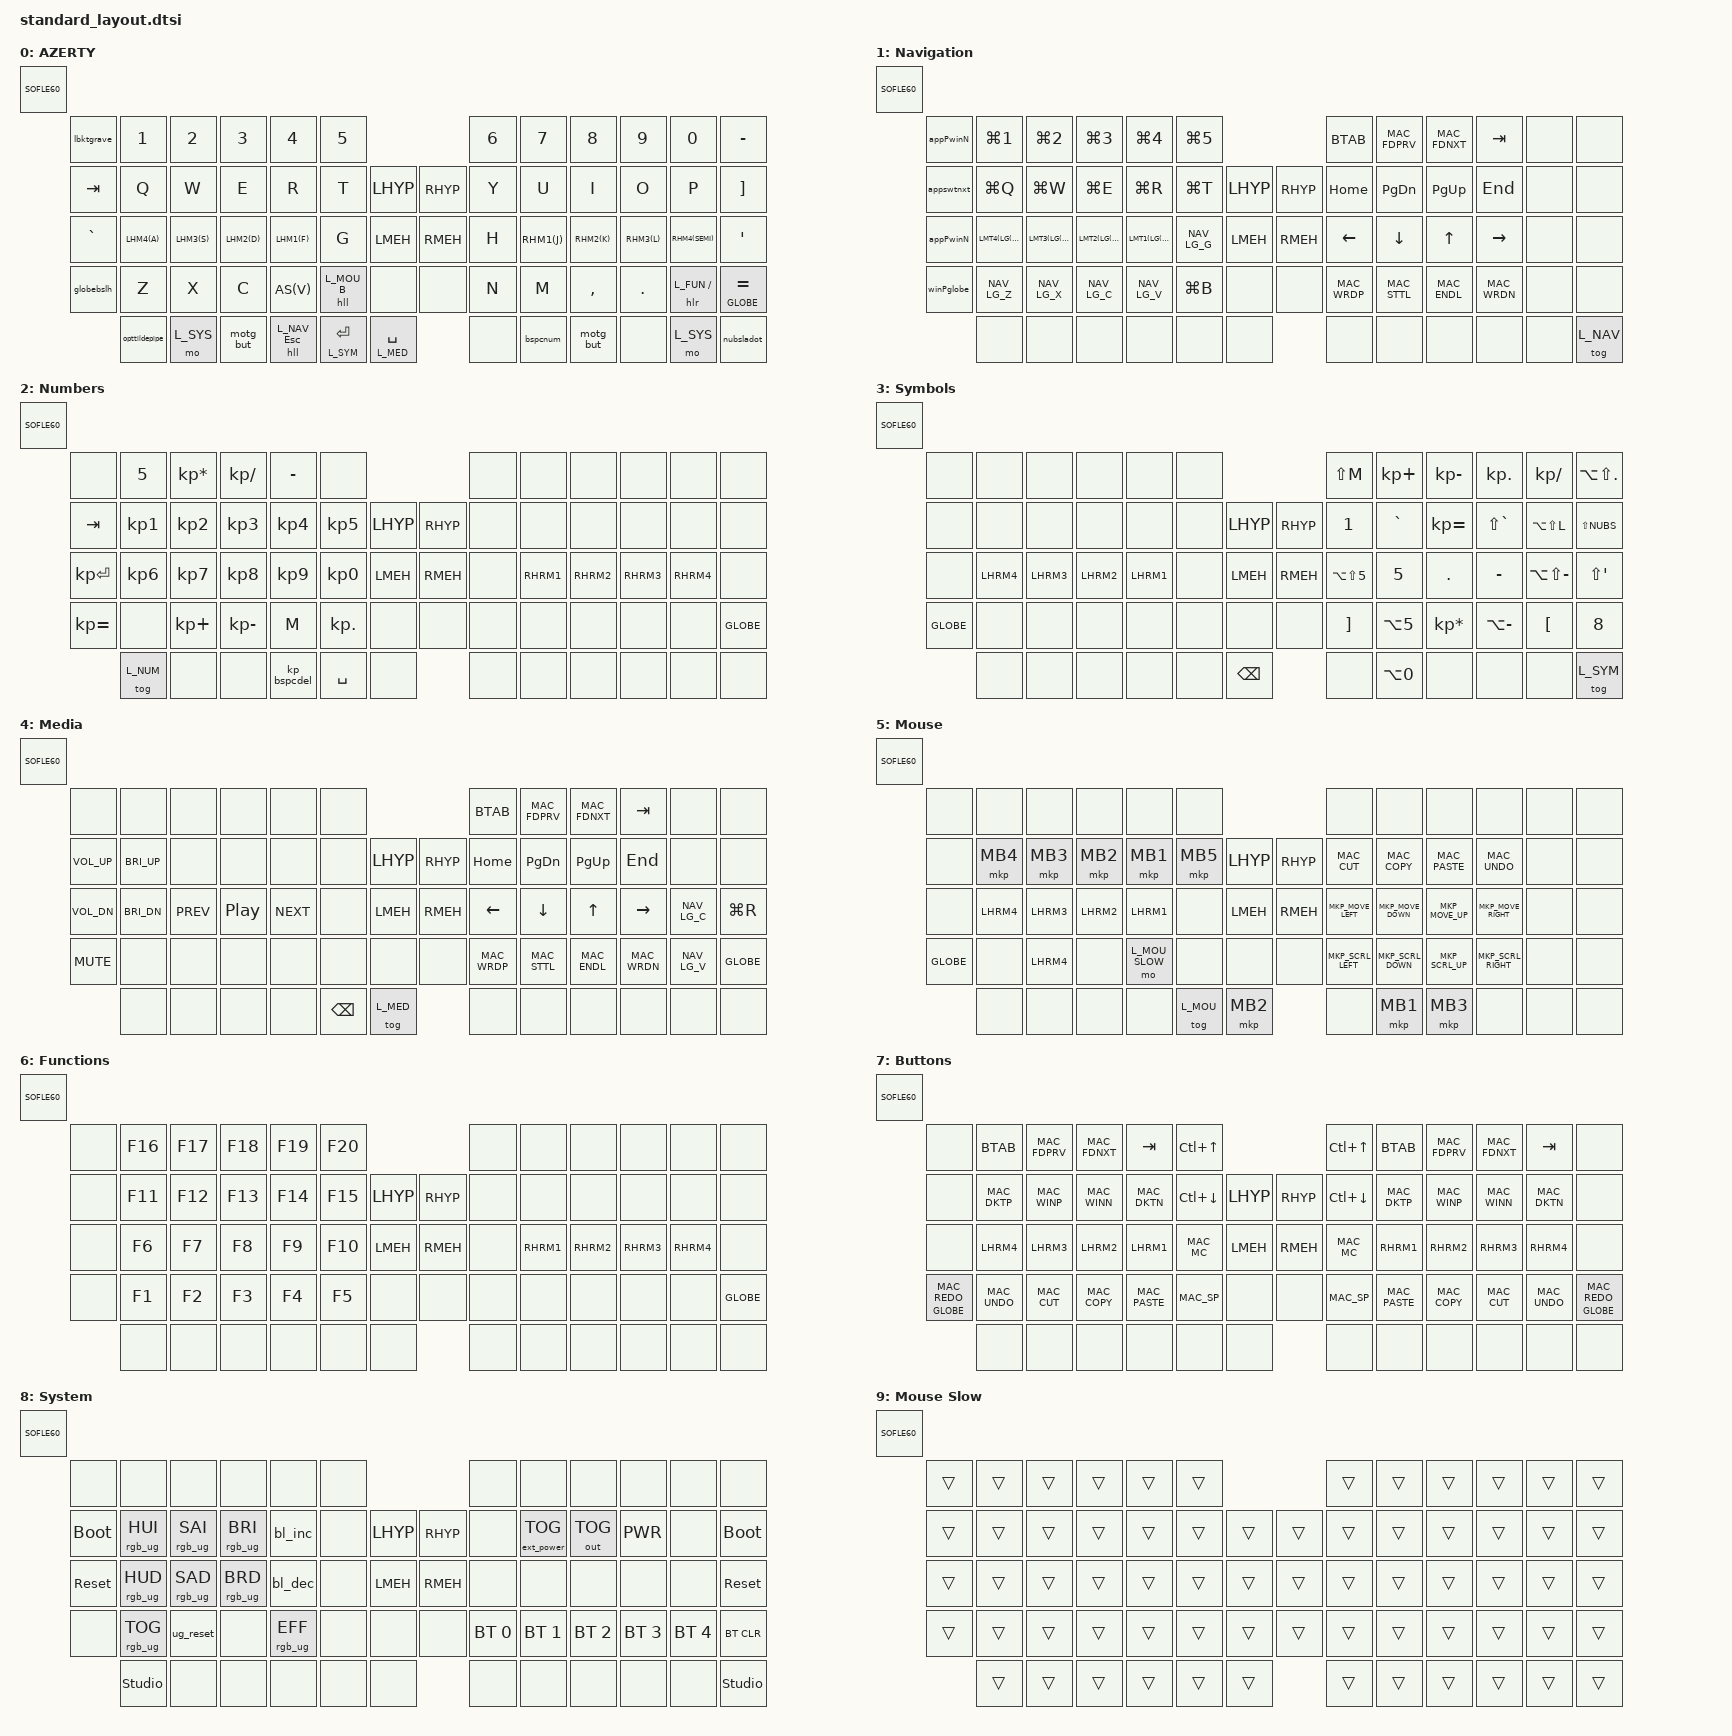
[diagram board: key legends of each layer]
/*
 * Copyright (c) 2024 Thiago Alves
 *
 * SPDX-License-Identifier: MIT
 */

// Éditeur : pas de retour à la ligne forcé sur les longues lignes ; police avec glyphes Nerd Fonts si besoin.

#include <behaviors.dtsi>
#include <dt-bindings/zmk/backlight.h>
#include <dt-bindings/zmk/bt.h>
#include <dt-bindings/zmk/ext_power.h>
#include <dt-bindings/zmk/keys.h>
#include <dt-bindings/zmk/mouse.h>
#include <dt-bindings/zmk/outputs.h>
#include <dt-bindings/zmk/rgb.h>

#include "specialkeys.dtsi"
#include "homerowmods.dtsi"
#include "autoshift.dtsi"
#include "keymap_drawer.dtsi"

#define L_QWT 0
#define L_NAV 1
#define L_NUM 2
#define L_SYM 3
#define L_MED 4
#define L_MOU 5
#define L_FUN 6
#define L_BUT 7
#define L_SYS 8
#define L_MOU_SLOW 9

&caps_word {
  continue-list = <UNDERSCORE MINUS BSPC>;
};

/*
 * Raccourcis P_* : config Sofle actuelle (sofle.keymap) = hold-tap Functions +
 * Mouse, sans hold-tap Buttons. Pour d’autres combinaisons, réintroduire les
 * branches Townk d’origine.
 */
#define P_SF4_QWT  &motg_but
#define P_SF4_BUT  &none
#define P_SB4_BUT  &kp MAC_UNDO
#define P_RB4_QWT  &hlr L_FUN FSLH
#define P_RB3_QWT  &kp DOT
#define P_RF3_QWT  &none
#define P_RF3_FUN  &none
#define P_RB3_FUN  &none
#define P_RB4_FUN  &none
#define P_LT54_NUM  &tog L_NUM
#define P_LT65_NAV  &tog L_NAV
#define P_LT65_SYM  &tog L_SYM
#define P_LB4_QWT  &kp Z
#define P_LB3_QWT  &kp X
#define P_LB5_QWT  &hll L_MOU B
#define P_LF3_QWT  &none
#define P_LF3_MOU  &none
#define P_LB4_MOU  &none
#define P_LT58_MOU  &tog L_MOU
#define P_MOUSE_SLOW  &mo L_MOU_SLOW

#include "mouse.dtsi"

// Comportements dédiés (autres : specialkeys, homerowmods, autoshift)
/ {
  behaviors {
    bspcnav: backspace_or_del_and_layer_nav {
      compatible = "zmk,behavior-mod-morph";
      #binding-cells = <0>;
      bindings = <&hll L_NAV BSPC>, <&kp DEL>;
      mods = <(MOD_LSFT|MOD_RSFT)>;
    };

    bspcnum: backspace_or_del_and_layer_num {
      compatible = "zmk,behavior-mod-morph";
      #binding-cells = <0>;
      bindings = <&hlr L_NUM BSPC>, <&kp DEL>;
      mods = <(MOD_LSFT|MOD_RSFT)>;
    };

    motg_nav: momentary_or_toggle_layer_nav {
      compatible = "zmk,behavior-tap-dance";
      #binding-cells = <0>;
      tapping-term-ms = <200>;
      bindings = <&mo L_NAV>, <&tog L_NAV>;
    };

    motg_but: momentary_or_toggle_layer_but {
      compatible = "zmk,behavior-tap-dance";
      #binding-cells = <0>;
      tapping-term-ms = <200>;
      bindings = <&mo L_BUT>, <&tog L_BUT>;
    };

    motg_fun: momentary_or_toggle_layer_fun {
      compatible = "zmk,behavior-tap-dance";
      #binding-cells = <0>;
      tapping-term-ms = <200>;
      bindings = <&mo L_FUN>, <&tog L_FUN>;
    };

    motg_mou: momentary_or_toggle_layer_mou {
      compatible = "zmk,behavior-tap-dance";
      #binding-cells = <0>;
      tapping-term-ms = <200>;
      bindings = <&mo L_MOU>, <&tog L_MOU>;
    };

    /* ⇧+tap → ⌥⇧1 ; sinon &hml GLOBE BSLH (hold-tap : phandles uniquement — pas de &kp dans bindings du HT). */
    globebslh_shift: globe_bslh_or_opt_shift_n1 {
      compatible = "zmk,behavior-mod-morph";
      #binding-cells = <0>;
      bindings = <&hml GLOBE BSLH>, <&kp LA(LS(N1))>;
      mods = <(MOD_LSFT|MOD_RSFT)>;
      keep-mods = <(MOD_LSFT|MOD_RSFT)>;
    };

    globebslh: globe_or_backslash {
      compatible = "zmk,behavior-mod-morph";
      #binding-cells = <0>;
      bindings = <&globebslh_shift>, <&kp TILDE>;
      mods = <(MOD_LGUI|MOD_RGUI)>;
      keep-mods = <(MOD_LGUI|MOD_RGUI)>;
    };

    /* Cmd maintenu : BTAB = LS(TAB) ; keep-mods GUI → ⌘⇧⇥ (app précédente, macOS). */
    lbktgrave: left_bracket_or_cmd_shift_tab {
      compatible = "zmk,behavior-mod-morph";
      #binding-cells = <0>;
      bindings = <&kp LBKT>, <&kp BTAB>;
      mods = <(MOD_LGUI|MOD_RGUI)>;
      keep-mods = <(MOD_LGUI|MOD_RGUI)>;
    };

    /* RC(4,0) macOS : ⌥n → tilde mort ~ ; ⇧+tap → |.
     * Le mod-morph s’active déjà avec ⇧ physiquement tenu : ne pas envoyer LS(L) (double ⇧ HID).
     * On n’ajoute que ⌥ puis L nu ; le rapport garde le ⇧ déjà enfoncé → ⌥⇧L → |. */
    opttildepipe_pipe: opttildepipe_pipe_chord {
      compatible = "zmk,behavior-macro";
      #binding-cells = <0>;
      wait-ms = <0>;
      tap-ms = <8>;
      bindings =
        <&macro_press &kp LALT>,
        <&macro_tap &kp L>,
        <&macro_release &kp LALT>;
    };

    opttildepipe: option_n_tilde_or_shift_pipe {
      compatible = "zmk,behavior-mod-morph";
      #binding-cells = <0>;
      bindings = <&kp LA(N)>, <&opttildepipe_pipe>;
      mods = <(MOD_LSFT|MOD_RSFT)>;
    };

    /* RC(4,11) : tap → LS(DOT) (/ AZERTY) ; ⇧+tap → LA(DOT) (⇧ tenu + ⌥+. → \ macOS FR, sans LS redondant). */
    dotslsh: dot_slash_or_backslash {
      compatible = "zmk,behavior-mod-morph";
      #binding-cells = <0>;
      bindings = <&kp LS(DOT)>, <&kp LA(DOT)>;
      mods = <(MOD_LSFT|MOD_RSFT)>;
      keep-mods = <(MOD_LSFT|MOD_RSFT)>;
    };

    /* MAIN (4,11) : tap → NUBS ; ⇧+tap → LA(DOT) (même branche ⇧ que dotslsh). */
    nubsladot: nubs_or_opt_dot_with_shift {
      compatible = "zmk,behavior-mod-morph";
      #binding-cells = <0>;
      bindings = <&kp NUBS>, <&kp LA(DOT)>;
      mods = <(MOD_LSFT|MOD_RSFT)>;
      keep-mods = <(MOD_LSFT|MOD_RSFT)>;
    };

    gravecaps: grave_or_capsword {
      compatible = "zmk,behavior-tap-dance";
      #binding-cells = <0>;
      tapping-term-ms = <200>;
      bindings = <&kp GRAVE>, <&caps_word>;
    };

    sqtcaps: singlequote_or_capsword {
      compatible = "zmk,behavior-tap-dance";
      #binding-cells = <0>;
      tapping-term-ms = <200>;
      bindings = <&kp SQT>, <&caps_word>;
    };

    appswtnxt: application_switch_next {
      compatible = "zmk,behavior-tri-state";
      #binding-cells = <0>;
      bindings = <&kt LGUI>, <&kp TAB>, <&kt LGUI>;
      ignored-key-positions = <LT5 LM5>;
    };

    winswtnxt: window_switch_next {
      compatible = "zmk,behavior-tri-state";
      #binding-cells = <0>;
      bindings = <&kt LGUI>, <&kp GRAVE>, <&kt LGUI>;
      ignored-key-positions = <LB5 LM5>;
    };

    appPwinN: application_switch_previous_window_next {
      compatible = "zmk,behavior-mod-morph";
      #binding-cells = <0>;
      bindings = <&winswtnxt>, <&kp GRAVE>;
      mods = <(MOD_LGUI|MOD_RGUI)>;
      keep-mods = <(MOD_LGUI|MOD_RGUI)>;
    };

    winPglobe: window_previous_globe {
      compatible = "zmk,behavior-mod-morph";
      #binding-cells = <0>;
      bindings = <&kp GLOBE>, <&kp TILDE>;
      mods = <(MOD_LGUI|MOD_RGUI)>;
      keep-mods = <(MOD_LGUI|MOD_RGUI)>;
    };
  };
};

/ {
    combos {
        compatible = "zmk,combos";

        combo_caps_word {
            timeout-ms = <75>;
            key-positions = COMBO_KEY_CAPS_WORD;
            layers = <L_QWT>;
            bindings = <&caps_word>;
        };
    };
};

/ {
  keymap {
    compatible = "zmk,keymap";

    /* Pouces : entrée SOFLE60 = 12 paramètres (K54–K65) ; sortie 10 touches sans K60/K63.
     * (4,0)=&opttildepipe ; (4,11) MAIN=&nubsladot ; le reste aligné Townk (K54,K55,K57,K58,K61,K62,K64,K65).
     *
     * 4ᵉ rangée entrée : K46 et K47 ne sont pas émis dans la matrice sortie — la macro SOFLE60
     * (sofle.keymap) y place K18 et K19 (LHYP/RHYP). &none sur K46–K47 évite les bindings fantômes. */

    MAIN {
      display-name = "AZERTY";
      /* Rangée 0 : chiffres HID classiques (&kp N1…), sans mod-morph kp_rNx (symbole tap / chiffre+Shift).
       * K11 ↔ K25 : mêmes codes qu’avant, positions inversées (RBKT sur lettres, MINUS sur chiffres). */
      bindings = <SOFLE60(
        &lbktgrave, &kp N1,    &kp N2,    &kp N3,    &kp N4,   &kp N5,                                &kp N6,        &kp N7,    &kp N8,    &kp N9,    &kp N0,     &kp MINUS,
        &kp TAB,    &kp Q,     &kp W,     &kp E,     &kp R,    &kp T,         &kp LHYP,    &kp RHYP,  &kp Y,         &kp U,     &kp I,     &kp O,     &kp P,      &kp RBKT,
        &kp GRAVE,  LHM4(A),   LHM3(S),   LHM2(D),   LHM1(F),  &kp G,         &kp LMEH,    &kp RMEH,  &kp H,         RHM1(J),   RHM2(K),   RHM3(L),   RHM4(SEMI), &kp SQT,
        &globebslh, P_LB4_QWT, P_LB3_QWT, &kp C,     AS(V),    P_LB5_QWT,     &none,       &none, &kp N,         &kp M,     &kp COMMA, P_RB3_QWT, P_RB4_QWT,  &hmr GLOBE EQUAL,
                    &opttildepipe, &mo L_SYS, P_SF4_QWT, &hll L_NAV ESC, &lt L_SYM RET, &lt L_MED SPACE, &none, &bspcnum, P_SF4_QWT, &none, &mo L_SYS, &nubsladot
      )>;
      sensor-bindings = <&mouscrl SCRLDN SCRLUP &inc_dec_kp C_VOL_UP C_VOL_DN>;
    };

    NAV {
      display-name = "Navigation";
      bindings = <SOFLE60(
        &appPwinN,  &kp LG(N1),  &kp LG(N2),  &kp LG(N3),  &kp LG(N4),  &kp LG(N5),                         &kp BTAB,     &kp MAC_FDPRV, &kp MAC_FDNXT, &kp TAB,      &none, &none,
        &appswtnxt, &kp LG(Q),   &kp LG(W),   &kp LG(E),   &kp LG(R),   &kp LG(T),  &kp LHYP,    &kp RHYP,  &kp HOME,     &kp PG_DN,     &kp PG_UP,     &kp END,      &none, &none,
        &appPwinN,  LMT4(LG(A)), LMT3(LG(S)), LMT2(LG(D)), LMT1(LG(F)), NAV_LG_G,   &kp LMEH,    &kp RMEH,  &kp LEFT,     &kp DOWN,      &kp UP,        &kp RIGHT,    &none, &none,
        &winPglobe, NAV_LG_Z,    NAV_LG_X,    NAV_LG_C,    NAV_LG_V,    &kp LG(B),  &none,       &none,     &kp MAC_WRDP, &kp MAC_STTL,  &kp MAC_ENDL,  &kp MAC_WRDN, &none, &none,
                    &none,       &none,       &none,       &none,      &none,      &none,       &none,     &none, &none,        &none,         &none,         P_LT65_NAV
      )>;
      sensor-bindings = <&mouscrl SCRLDN SCRLUP &inc_dec_kp C_VOL_UP C_VOL_DN>;
    };

    NUM {
      display-name = "Numbers";
      /* (0,1) N5, (0,4) MINUS ; (1,1)–(2,5) pavé HID ; (3,1) none, (3,4) M, (3,5) KP_DOT. */
      bindings = <SOFLE60(
        &none,        &kp N5,   &kp KP_MULTIPLY, &kp KP_DIVIDE, &kp MINUS, &none,                          &none, &none,      &none,     &none,     &none,     &none,
        &kp TAB,      &kp KP_N1, &kp KP_N2, &kp KP_N3, &kp KP_N4, &kp KP_N5, &kp LHYP,    &kp RHYP,  &none, &none,      &none,     &none,     &none,     &none,
        &kp KP_ENTER, &kp KP_N6, &kp KP_N7, &kp KP_N8, &kp KP_N9, &kp KP_N0, &kp LMEH,    &kp RMEH,  &none, &kp RHRM1,  &kp RHRM2, &kp RHRM3, &kp RHRM4, &none,
        &kp KP_EQUAL, &none, &kp KP_PLUS, &kp KP_MINUS, &kp M, &kp KP_DOT, &none,       &none, &none, &none,      &none,     &none,     &none,     &kp GLOBE,
                      P_LT54_NUM,  &none,    &none,     &kp_bspcdel, &kp SPACE,  &none,      &none,     &none, &none,     &none,     &none,     &none
      )>;
      sensor-bindings = <&mouscrl SCRLDN SCRLUP &inc_dec_kp C_VOL_UP C_VOL_DN>;
    };

    SYMBOL {
      display-name = "Symbols";
      /* Pavé droit layer 3 : séquences imposées (RC + Option/Shift) — voir discussion keymap. */
      bindings = <SOFLE60(
        &none,     &none,     &none,     &none,     &none,     &none,                              &kp LS(M), &kp KP_PLUS, &kp KP_MINUS, &kp KP_DOT, &kp KP_SLASH, &kp LA(LS(DOT)),
        &none,     &none,     &none,     &none,     &none,     &none,      &kp LHYP,    &kp RHYP,  &kp N1,    &kp GRAVE, &kp KP_EQUAL, &kp LS(GRAVE), &kp LA(LS(L)), &kp LS(NUBS),
        &none,     &kp LHRM4, &kp LHRM3, &kp LHRM2, &kp LHRM1, &none,      &kp LMEH,    &kp RMEH,  &kp LA(LS(N5)), &kp N5, &kp DOT, &kp MINUS, &kp LA(LS(MINUS)), &kp LS(SQT),
        &kp GLOBE, &none,     &none,     &none,     &none,     &none,      &none,       &none, &kp RBKT,  &kp LA(N5), &kp KP_MULTIPLY, &kp LA(MINUS), &kp LBKT, &kp N8,
                   &none,     &none,     &none,     &none,     &none,     &kp BSPC,    &none,     &kp LA(N0), &none,     &none,     &none,     P_LT65_SYM
      )>;
      sensor-bindings = <&mouscrl SCRLDN SCRLUP &inc_dec_kp C_VOL_UP C_VOL_DN>;
    };

    MEDIA {
      display-name = "Media";
      /* K06–K09, K20–K23, K34–K37, K48–K51 : mêmes bindings que NAV (Navigation). */
      bindings = <SOFLE60(
        &none,        &none,        &none,      &none,    &none,      &none,                              &kp BTAB,     &kp MAC_FDPRV, &kp MAC_FDNXT, &kp TAB,      &none, &none,
        &kp C_VOL_UP, &kp C_BRI_UP, &none,      &none,    &none,      &none,      &kp LHYP,    &kp RHYP,  &kp HOME,     &kp PG_DN,     &kp PG_UP,     &kp END,      &none, &none,
        &kp C_VOL_DN, &kp C_BRI_DN, &kp C_PREV, &kp C_PP, &kp C_NEXT, &none,      &kp LMEH,    &kp RMEH,  &kp LEFT,     &kp DOWN,      &kp UP,        &kp RIGHT,    NAV_LG_C,     &kp LG(R),
        &kp C_MUTE,   &none,        &none,      &none,    &none,      &none,      &none,       &none, &kp MAC_WRDP, &kp MAC_STTL,  &kp MAC_ENDL,  &kp MAC_WRDN, NAV_LG_V, &kp GLOBE,
                      /* K58 BSPC · K59 verrou */
                      &none, &none, &none, &none, &kp BSPC, &tog L_MED, &none, &none, &none, &none, &none, &none
      )>;
      sensor-bindings = <&mouscrl SCRLDN SCRLUP &inc_dec_kp C_VOL_UP C_VOL_DN>;
    };

    MOUSE {
      display-name = "Mouse";
      bindings = <SOFLE60(
        &none,     &none,     &none,     &none,     &none,     &none,                            &none,         &none,         &none,         &none,          &none, &none,
        &none,     &mkp MB4,  &mkp MB3,  &mkp MB2,  &mkp MB1,  &mkp MB5, &kp LHYP,    &kp RHYP,  &kp MAC_CUT,   &kp MAC_COPY,  &kp MAC_PASTE, &kp MAC_UNDO,   &none, &none,
        &none,     &kp LHRM4, &kp LHRM3, &kp LHRM2, &kp LHRM1, &none,    &kp LMEH,    &kp RMEH,  MKP_MOVE_LEFT, MKP_MOVE_DOWN, MKP_MOVE_UP,   MKP_MOVE_RIGHT, &none, &none,
        &kp GLOBE, P_LB4_MOU, &kp LHRM4, &none,     P_MOUSE_SLOW, &none,    &none,       &none,     MKP_SCRL_LEFT, MKP_SCRL_DOWN, MKP_SCRL_UP,   MKP_SCRL_RIGHT, &none, &none,
                   &none,     &none,     &none,     &none,     P_LT58_MOU,    &mkp MB2,    &none,     &mkp MB1,      &mkp MB3,      &none,     &none,       &none
      )>;
      sensor-bindings = <&mouscrl SCRLDN SCRLUP &inc_dec_kp C_VOL_UP C_VOL_DN>;
    };

    FUNCTIONS {
      display-name = "Functions";
      bindings = <SOFLE60(
        &none, &kp F16, &kp F17, &kp F18, &kp F19, &kp F20,                         &none, &none,     &none,     &none,     &none,     &none,
        &none, &kp F11, &kp F12, &kp F13, &kp F14, &kp F15, &kp LHYP,    &kp RHYP,  &none, &none,     &none,     &none,     &none,     &none,
        &none, &kp F6,  &kp F7,  &kp F8,  &kp F9,  &kp F10, &kp LMEH,    &kp RMEH,  &none, &kp RHRM1, &kp RHRM2, &kp RHRM3, &kp RHRM4, &none,
        &none, &kp F1,  &kp F2,  &kp F3,  &kp F4,  &kp F5,  &none,       &none, &none, &none,     &none,     P_RB3_FUN, P_RB4_FUN, &kp GLOBE,
               &none, &none,   &none,   &none,   &none,   &none,      &none,     &none, &none,     &none,     &none,     &none
      )>;
      sensor-bindings = <&mouscrl SCRLDN SCRLUP &inc_dec_kp C_VOL_UP C_VOL_DN>;
    };

    BUTTON {
      display-name = "Buttons";
      bindings = <SOFLE60(
        &none,              &kp BTAB,     &kp MAC_FDPRV, &kp MAC_FDNXT, &kp TAB,       &kp LC(UP),                             &kp LC(UP),     &kp BTAB,      &kp MAC_FDPRV, &kp MAC_FDNXT, &kp TAB,      &none,
        &none,              &kp MAC_DKTP, &kp MAC_WINP,  &kp MAC_WINN,  &kp MAC_DKTN,  &kp LC(DOWN), &kp LHYP,    &kp RHYP,  &kp LC(DOWN), &kp MAC_DKTP,  &kp MAC_WINP,  &kp MAC_WINN,  &kp MAC_DKTN, &none,
        &none,              &kp LHRM4,    &kp LHRM3,     &kp LHRM2,     &kp LHRM1,     &kp MAC_MC,     &kp LMEH,    &kp RMEH,  &kp MAC_MC,     &kp RHRM1,     &kp RHRM2,     &kp RHRM3,     &kp RHRM4,    &none,
        &mt GLOBE MAC_REDO, P_SB4_BUT,    &kp MAC_CUT,   &kp MAC_COPY,  &kp MAC_PASTE, &kp MAC_SP,     &none,       &none, &kp MAC_SP,     &kp MAC_PASTE, &kp MAC_COPY,  &kp MAC_CUT,   P_SB4_BUT,    &mt GLOBE MAC_REDO,
                            &none,      &none,         &none,    &none,         &none,          &none,       &none,     &none,          &none, &none, &none, &none
      )>;
      sensor-bindings = <&mouscrl SCRLDN SCRLUP &inc_dec_kp C_VOL_UP C_VOL_DN>;
    };

    SYSTEM {
      display-name = "System";
      bindings = <SOFLE60(
        &none,       &none,           &none,           &none,           &none,   &none,                                     &none,        &none,        &none,        &none,        &none,         &none,
        &bootloader, &rgb_ug RGB_HUI, &rgb_ug RGB_SAI, &rgb_ug RGB_BRI, &bl_inc, &none,            &kp LHYP,    &kp RHYP,  &none,        &ext_power EP_TOG, &out OUT_TOG, &kp C_PWR,   &none,        &bootloader,
        &sys_reset,  &rgb_ug RGB_HUD, &rgb_ug RGB_SAD, &rgb_ug RGB_BRD, &bl_dec, &none,            &kp LMEH,    &kp RMEH,  &none,        &none,        &none,        &none,        &none,         &sys_reset,
        &none,       &rgb_ug RGB_TOG, &ug_reset,       &none,           &rgb_ug RGB_EFF, &none,     &none,       &none, &bt BT_SEL 0, &bt BT_SEL 1, &bt BT_SEL 2, &bt BT_SEL 3, &bt BT_SEL 4,  &bt BT_CLR,
                     &studio_unlock,  &none,      &none,           &none,   &none,            &none,       &none,     &none,        &none,        &none,        &none,     &studio_unlock
      )>;
      sensor-bindings = <&mouscrl SCRLDN SCRLUP &inc_dec_kp C_VOL_UP C_VOL_DN>;
    };

    MOUSE_SLOW {
      display-name = "Mouse Slow";
      /* Overlay frein : &trans + scaler mmv (mouse.dtsi). */
      bindings = <SOFLE60(
        &trans, &trans, &trans, &trans, &trans, &trans,                         &trans, &trans, &trans, &trans, &trans, &trans,
        &trans, &trans, &trans, &trans, &trans, &trans, &trans, &trans, &trans, &trans, &trans, &trans, &trans, &trans,
        &trans, &trans, &trans, &trans, &trans, &trans, &trans, &trans, &trans, &trans, &trans, &trans, &trans, &trans,
        &trans, &trans, &trans, &trans, &trans, &trans, &trans, &trans, &trans, &trans, &trans, &trans, &trans, &trans,
               &trans, &trans, &trans, &trans, &trans, &trans, &trans, &trans, &trans, &trans, &trans, &trans
      )>;
    };
  };
};
